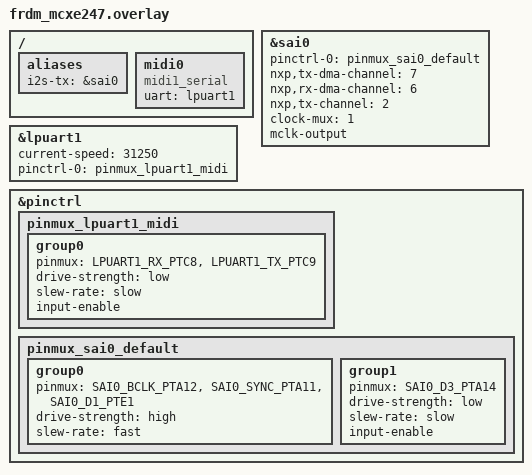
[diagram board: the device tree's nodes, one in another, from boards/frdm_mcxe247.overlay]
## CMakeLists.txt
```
# Copyright 2026 Jan-Willem Smaal <usenet@gispen.org>
# SPDX-License-Identifier: Apache-2.0

cmake_minimum_required(VERSION 3.20.0)
set(KCONFIG_ROOT ${CMAKE_CURRENT_SOURCE_DIR}/Kconfig)
find_package(Zephyr REQUIRED HINTS $ENV{ZEPHYR_BASE})
project(i2s_generator)

target_sources(app PRIVATE 
    src/main.c 
    src/generators.c
    src/shell.c
)

target_include_directories(app PRIVATE src)
```

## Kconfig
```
# Copyright 2026 Jan-Willem Smaal <usenet@gispen.org>
# SPDX-License-Identifier: Apache-2.0

menu "I2S Signal Generator Options"

config AUDIO_SAMPLE_RATE
	int "Sample Rate (Hz)"
	default 192000
	help
	  The sample rate of the generated I2S stream.

config AUDIO_BIT_WIDTH
	int "Sample Bit Width"
	default 16
	range 16 32
	help
	  The bit width of each audio sample (16 or 32).

endmenu

source "Kconfig.zephyr"
```

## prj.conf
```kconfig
CONFIG_GPIO=y
CONFIG_I2S=y
CONFIG_CMSIS_DSP=y
CONFIG_CMSIS_DSP_FASTMATH=y
CONFIG_CMSIS_DSP_BASICMATH=y
CONFIG_CMSIS_DSP_FILTERING=y
CONFIG_I2S_TX_BLOCK_COUNT=8
CONFIG_LOG=y
CONFIG_SHELL=y
CONFIG_SHELL_PROMPT_UART="I2S-Gen:~$ "
CONFIG_SHELL_VT100_COLORS=y
CONFIG_SHELL_HISTORY=y
CONFIG_SHELL_METAKEYS=y
CONFIG_SHELL_HELP=y

# Restore shell infrastructure for backspace, completion, and history
CONFIG_SHELL_VT100_COLORS=y
CONFIG_SHELL_CMDS=y
CONFIG_SHELL_HISTORY=y
CONFIG_SHELL_METAKEYS=y
CONFIG_SHELL_TAB_AUTOCOMPLETION=y
CONFIG_SHELL_HELP=y

# Keep non-shell system commands disabled for a cleaner interface
CONFIG_KERNEL_SHELL=n
CONFIG_DEVICE_SHELL=n
CONFIG_DEVMEM_SHELL=n
CONFIG_LOG_CMDS=n
CONFIG_STATS_SHELL=n
CONFIG_DATE_SHELL=n

CONFIG_CBPRINTF_FP_SUPPORT=y
CONFIG_TEST_RANDOM_GENERATOR=y

# High precision heap/stack for DSP
CONFIG_MAIN_STACK_SIZE=4096
CONFIG_SYSTEM_WORKQUEUE_STACK_SIZE=4096
```

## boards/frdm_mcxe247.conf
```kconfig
# Copyright 2026 Jan-Willem Smaal <usenet@gispen.org>
# SPDX-License-Identifier: Apache-2.0
CONFIG_I2S_HAS_PLL_SETTING=n

# Fix for a bug with the watchdog in v4.4.0 
# we need to enable the watchdog in the Kconfig
# but disable it right away at boot.
CONFIG_WATCHDOG=y
CONFIG_WDT_DISABLE_AT_BOOT=y
```

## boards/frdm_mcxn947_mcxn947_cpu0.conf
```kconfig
# MCX N-series does not use the i.MX RT style Audio PLL configuration in the SAI driver.
# Disabling this prevents a compilation error in i2s_mcux_sai.c.
CONFIG_I2S_HAS_PLL_SETTING=n
```

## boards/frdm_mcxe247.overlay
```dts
/*
 * Copyright 2026 Jan-Willem Smaal <usenet@gispen.org>
 * SPDX-License-Identifier: Apache-2.0
 */

#include <nxp/mcx/MCXE247VLQ-pinctrl.h>

/ {
	aliases {
		i2s-tx = &sai0;
	};

	midi0: midi0 {
		status = "okay";
		compatible = "midi1_serial";
		uart = <&lpuart1>;
	};
};

&sai0 {
	status = "okay";
	pinctrl-0 = <&pinmux_sai0_default>;
	pinctrl-names = "default";
	
	/* REQUIRED properties from binding documentation */
	nxp,tx-dma-channel = <7>;
	nxp,rx-dma-channel = <6>;
	
	/* User Truth: J1 Pin 5 is PTE1 which is SAI0_D1 (Channel 1) */
	nxp,tx-channel = <2>; 
	
	/* Select standard functional clock for SAI root */
	clock-mux = <1>; 
	
	mclk-output;
};

/* MIDI/Console on mikroBUS UART (PTC8/PTC9) */
&lpuart1 {
	status = "okay";
	current-speed = <31250>;
	pinctrl-0 = <&pinmux_lpuart1_midi>;
	pinctrl-names = "default";
};

&pinctrl {
	/* Standard pins with input-enable for RX */
	pinmux_lpuart1_midi: pinmux_lpuart1_midi {
		group0 {
			pinmux = <LPUART1_RX_PTC8>,
				 <LPUART1_TX_PTC9>;
			drive-strength = "low";
			slew-rate = "slow";
			input-enable;
		};
	};

	/* SAI0 (Verified User Truth Mapping) */
	pinmux_sai0_default: pinmux_sai0_default {
		group0 {
			pinmux = <SAI0_BCLK_PTA12>,   /* J1 Pin 9  - Bit Clock */
				 <SAI0_SYNC_PTA11>,   /* J1 Pin 7  - Frame Sync (LRCK) */
				 <SAI0_D1_PTE1>;      /* J1 Pin 5  - Data Out (TX_DAT) */
			drive-strength = "high";
			slew-rate = "fast";
		};
		group1 {
			pinmux = <SAI0_D3_PTA14>;     /* J1 Pin 15 - Data In (RX_DAT) */
			drive-strength = "low";
			slew-rate = "slow";
			input-enable;
		};
	};
};
```

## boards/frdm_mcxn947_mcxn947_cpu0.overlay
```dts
/*
 * Copyright 2026 Jan-Willem Smaal <usenet@gispen.org>
 * SPDX-License-Identifier: Apache-2.0
 * 
 * Proven configuration for PCM5102A on FRDM-MCXN947
 */

&sai1 {
	status = "okay";
	pinctrl-0 = <&pinmux_sai1_custom>;
	pinctrl-names = "default";
	nxp,tx-channel = <1>; /* Bitmask: 1 = Channel 0 (TXD0) */
	mclk-output;          /* MANDATORY for MCXN947 to enable internal clock generator */
};

&sai0 {
	status = "disabled";
};

&flexcomm6 {
	status = "disabled";
};

&pinctrl {
	pinmux_sai1_custom: pinmux_sai1_custom {
		group0 {
			pinmux = <SAI1_TX_BCLK_PIO3_16>,   /* J1 Pin 1  - Bit Clock */
				 <SAI1_TX_FS_PIO3_17>,     /* J1 Pin 11 - Frame Sync (LRCK) */
				 <SAI1_TXD0_PIO3_20>,      /* J1 Pin 5  - Data Out */
				 <SAI1_RX_BCLK_PIO3_18>;   /* J1 Pin 9  - Bit Clock (Swapped) */
			drive-strength = "high";
			slew-rate = "fast";
			input-enable;
		};
	};
};
```

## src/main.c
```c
/*
 * Copyright 2026 Jan-Willem Smaal <usenet@gispen.org>
 * SPDX-License-Identifier: Apache-2.0
 */

/**
 * @file main.c
 * @brief I2S Signal Generator Main Loop and Driver Integration
 * @author Jan-Willem Smaal <usenet@gispen.org>
 * @date 2026-05-27
 */

#include <zephyr/kernel.h>
#include <zephyr/drivers/i2s.h>
#include <zephyr/logging/log.h>
#include "generators.h"

LOG_MODULE_REGISTER(i2s_gen, LOG_LEVEL_INF);

#define SAMPLE_RATE CONFIG_AUDIO_SAMPLE_RATE
#define SAMPLE_BIT_WIDTH CONFIG_AUDIO_BIT_WIDTH
#define CHANNELS 2
#define SAMPLES_PER_FRAME 256
#define FRAME_SIZE (SAMPLES_PER_FRAME * CHANNELS * (SAMPLE_BIT_WIDTH / 8))
#define TX_BLOCK_COUNT 12
#define RX_BLOCK_COUNT 8

K_MEM_SLAB_DEFINE_STATIC(tx_slab, FRAME_SIZE, TX_BLOCK_COUNT, 4);
K_MEM_SLAB_DEFINE_STATIC(rx_slab, FRAME_SIZE, RX_BLOCK_COUNT, 4);

//static const struct device *const i2s_dev = DEVICE_DT_GET(DT_NODELABEL(sai1));
static const struct device *const i2s_dev = DEVICE_DT_GET(DT_ALIAS(i2s_tx));

static struct gen_state g_state;
static K_SEM_DEFINE(stream_start_sem, 0, 1);
static K_SEM_DEFINE(rx_ready_sem, 0, 1);
static bool stream_running = false;

struct gen_state *get_gen_state(void)
{
	return &g_state;
}

void audio_stream_start(void)
{
	if (!stream_running) {
		stream_running = true;
		k_sem_give(&stream_start_sem);
	}
}

void audio_stream_stop(void)
{
	if (stream_running) {
		stream_running = false;
		/* Use DROP to completely flush the TX queue and reset state */
		i2s_trigger(i2s_dev, I2S_DIR_TX, I2S_TRIGGER_DROP);
	}
}

static void audio_thread(void *p1, void *p2, void *p3)
{
	int ret;
	void *tx_buffer;

	while (1) {
		k_sem_take(&stream_start_sem, K_FOREVER);
		
		LOG_INF("Stream started");

		/* 
		 * Prime the DMA pump: On NXP MCUX SAI drivers, we MUST queue exactly 
		 * one audio block BEFORE issuing the START command.
		 */
		ret = k_mem_slab_alloc(&tx_slab, &tx_buffer, K_NO_WAIT);
		if (ret == 0) {
			gen_fill_buffer(&g_state, (int16_t *)tx_buffer, SAMPLES_PER_FRAME * CHANNELS);
			
			/* Use a block-friendly timeout to prevent EAGAIN (-35) on fast CPUs */
			ret = i2s_write(i2s_dev, tx_buffer, FRAME_SIZE);
			if (ret < 0 && ret != -EAGAIN) {
				LOG_ERR("I2S priming write failed: %d", ret);
				k_mem_slab_free(&tx_slab, tx_buffer);
				stream_running = false;
				continue;
			}
			/* If EAGAIN, we just proceed to start, the buffer wasn't queued but we'll catch up */
		}

		/* Start the hardware now that the queue has data */
		ret = i2s_trigger(i2s_dev, I2S_DIR_TX, I2S_TRIGGER_START);
		if (ret < 0) {
			LOG_ERR("I2S TX trigger start failed: %d", ret);
			stream_running = false;
			continue;
		}

		/* Main hot loop */
		while (stream_running) {
			ret = k_mem_slab_alloc(&tx_slab, &tx_buffer, K_NO_WAIT);
			if (ret < 0) {
				k_sleep(K_MSEC(1));
				continue;
			}

			gen_fill_buffer(&g_state, (int16_t *)tx_buffer, SAMPLES_PER_FRAME * CHANNELS);

			/* 
			 * Real-time audio: If the queue is full (-EAGAIN), do not block or retry.
			 * The time window has passed, so we simply drop this block and move on.
			 */
			ret = i2s_write(i2s_dev, tx_buffer, FRAME_SIZE);
			if (ret < 0) {
				k_mem_slab_free(&tx_slab, tx_buffer);
				if (ret != -EAGAIN) {
					LOG_ERR("I2S write failed: %d", ret);
					break;
				}
			}
		}
		
		LOG_INF("Stream stopped");
		stream_running = false;
	}
}

static void rx_sink_thread(void *p1, void *p2, void *p3)
{
	void *rx_buffer;
	size_t size;
	int ret;

	/* Wait for RX to be triggered in main */
	k_sem_take(&rx_ready_sem, K_FOREVER);

	while (1) {
		ret = i2s_read(i2s_dev, &rx_buffer, &size);
		if (ret == 0) {
			k_mem_slab_free(&rx_slab, rx_buffer);
		} else {
			k_sleep(K_MSEC(1));
		}
	}
}

K_THREAD_DEFINE(audio_tid, 2048, audio_thread, NULL, NULL, NULL, -2, 0, 0);
K_THREAD_DEFINE(rx_sink_tid, 1024, rx_sink_thread, NULL, NULL, NULL, -1, 0, 0);

int main(void)
{
	struct i2s_config conf;
	int ret;

	LOG_INF("I2S Signal Generator Ready.");

	if (!device_is_ready(i2s_dev)) {
		LOG_ERR("I2S device not ready");
		return -ENODEV;
	}

	conf.word_size = SAMPLE_BIT_WIDTH;
	conf.channels = CHANNELS;
	conf.format = I2S_FMT_DATA_FORMAT_I2S;
	conf.options = I2S_OPT_BIT_CLK_CONTROLLER | I2S_OPT_FRAME_CLK_CONTROLLER;
	conf.frame_clk_freq = SAMPLE_RATE;
	conf.block_size = FRAME_SIZE;
	conf.timeout = 2000;

	/* Configure TX */
	conf.mem_slab = &tx_slab;
	ret = i2s_configure(i2s_dev, I2S_DIR_TX, &conf);
	if (ret < 0) {
		LOG_ERR("I2S TX configure failed: %d", ret);
		return ret;
	}

	/* Configure RX for Clocks (Dummy Slab) */
	conf.mem_slab = &rx_slab;
	ret = i2s_configure(i2s_dev, I2S_DIR_RX, &conf);
	if (ret < 0) {
		LOG_ERR("I2S RX configure failed: %d", ret);
		return ret;
	}

	gen_init(&g_state, SAMPLE_RATE);

	/* Start Clocks (via RX). */
	ret = i2s_trigger(i2s_dev, I2S_DIR_RX, I2S_TRIGGER_START);
	if (ret < 0) {
		LOG_WRN("I2S RX (Clocks) start failed: %d", ret);
	} else {
		k_sem_give(&rx_ready_sem);
	}

	LOG_INF("Use 'gen' commands in shell to control.");

	return 0;
}
```

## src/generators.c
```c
/*
 * Copyright 2026 Jan-Willem Smaal <usenet@gispen.org>
 * SPDX-License-Identifier: Apache-2.0
 */

/**
 * @file generators.c
 * @brief CMSIS-DSP Waveform Generators Implementation (Encapsulated)
 * @author Jan-Willem Smaal <usenet@gispen.org>
 * @date 2026-05-27
 */

#include "generators.h"
#include <zephyr/random/random.h>
#include <math.h>
#include <string.h>

int gen_init(struct gen_state *state, uint32_t sample_rate)
{
	if (sample_rate == 0) {
		return -EINVAL;
	}

	memset(state, 0, sizeof(struct gen_state));
	state->type = WAVE_SINE;
	state->level = LEVEL_MAX;
	state->freq = 1000.0f;
	state->sample_rate = (float32_t)sample_rate;
	state->inv_sample_rate = 1.0f / state->sample_rate;
	state->scale = SCALE_MAX;
	
	/* Initialize safe defaults for statics */
	state->pink_indices = 1;
	state->lr_swap_left_active = true;

	return gen_set_frequency(state, state->freq);
}

void gen_set_type(struct gen_state *state, gen_type_t type)
{
	state->type = type;
	if (type == WAVE_DIRAC) {
		state->phase_acc = 0;
	}
}

int gen_set_frequency(struct gen_state *state, float freq_hz)
{
	if (freq_hz <= 0.0f || freq_hz > (state->sample_rate / 2.0f)) {
		return -EINVAL;
	}

	state->freq = freq_hz;
	/* Calculate phase increment in Q31 */
	state->phase_inc = (q31_t)((state->freq * state->inv_sample_rate) * NCO_RANGE);

	if (state->burst_active) {
		float32_t samples_per_cycle = state->sample_rate / state->freq;
		state->burst_on_samples = (uint32_t)(state->burst_on_cycles * samples_per_cycle);
		state->burst_off_samples = (uint32_t)(state->burst_off_cycles * samples_per_cycle);
	}
	
	return 0;
}

void gen_set_level(struct gen_state *state, gen_level_t level)
{
	state->level = level;
	switch (level) {
	case LEVEL_PRO:
		state->scale = SCALE_PRO;
		break;
	case LEVEL_CONSUMER:
		state->scale = SCALE_CONSUMER;
		break;
	case LEVEL_MAX:
	default:
		state->scale = SCALE_MAX;
		break;
	}
}

void gen_set_phase_offset(struct gen_state *state, float phase_deg)
{
	state->phase_offset = (q31_t)((phase_deg / DEGREES_PER_REV) * NCO_RANGE);
}

int gen_set_burst(struct gen_state *state, uint32_t on_cycles, uint32_t off_cycles)
{
	if (state->freq <= 0.0f) {
		return -EINVAL;
	}
	state->burst_on_cycles = on_cycles;
	state->burst_off_cycles = off_cycles;
	state->burst_active = true;
	state->burst_counter = 0;
	return gen_set_frequency(state, state->freq);
}

void gen_stop_burst(struct gen_state *state)
{
	state->burst_active = false;
}

int gen_set_sweep(struct gen_state *state, float start_hz, float end_hz, uint32_t duration_ms)
{
	float32_t nyquist = state->sample_rate / 2.0f;
	
	if (start_hz <= 0.0f || end_hz <= 0.0f || duration_ms == 0 ||
	    start_hz > nyquist || end_hz > nyquist) {
		return -EINVAL;
	}

	state->sweep_start_freq = start_hz;
	state->sweep_end_freq = end_hz;
	state->sweep_current_freq = start_hz;
	state->sweep_samples_current = 0;
	state->sweep_samples_total = (uint32_t)(duration_ms * (state->sample_rate / MS_PER_SEC));
	
	if (state->sweep_samples_total > 0) {
		state->sweep_multiplier = powf(end_hz / start_hz, 1.0f / (float32_t)state->sweep_samples_total);
		state->sweep_active = true;
	}
	
	return 0;
}

void gen_stop_sweep(struct gen_state *state)
{
	state->sweep_active = false;
	gen_set_frequency(state, state->freq);
}

static inline void update_sweep_phase(struct gen_state *state)
{
	if (state->sweep_active) {
		state->sweep_current_freq *= state->sweep_multiplier;
		state->sweep_samples_current++;
		
		if (state->sweep_samples_current >= state->sweep_samples_total) {
			state->sweep_current_freq = state->sweep_start_freq;
			state->sweep_samples_current = 0;
		}
		
		state->phase_inc = (q31_t)((state->sweep_current_freq * state->inv_sample_rate) * NCO_RANGE);
	}
}

static void fill_sine(struct gen_state *state, int16_t *buffer, uint32_t num_samples)
{
	for (uint32_t i = 0; i < num_samples; i += 2) {
		update_sweep_phase(state);

		q15_t angle_l = (q15_t)(state->phase_acc >> PHASE_TO_SINE_SHIFT);
		q15_t q_val_l = arm_sin_q15(angle_l);
		
		q15_t angle_r = (q15_t)((state->phase_acc + state->phase_offset) >> PHASE_TO_SINE_SHIFT);
		q15_t q_val_r = arm_sin_q15(angle_r);
		
		if (state->burst_active) {
			uint32_t period = state->burst_on_samples + state->burst_off_samples;
			if (state->burst_counter >= state->burst_on_samples) {
				q_val_l = 0;
				q_val_r = 0;
			}
			state->burst_counter++;
			if (state->burst_counter >= period) {
				state->burst_counter = 0;
			}
		}

		buffer[i] = q_val_l;
		buffer[i + 1] = q_val_r;
		
		state->phase_acc += state->phase_inc;
	}
}

static void fill_white_noise(struct gen_state *state, int16_t *buffer, uint32_t num_samples)
{
	for (uint32_t i = 0; i < num_samples; i += 2) {
		uint32_t r = sys_rand32_get();
		q15_t q_val = (q15_t)((r & UINT16_MAX) - Q15_MID_OFFSET);
		buffer[i] = q_val;
		buffer[i + 1] = q_val;
	}
}

static void fill_pink_noise(struct gen_state *state, int16_t *buffer, uint32_t num_samples)
{
	/* Pre-compute Q15 scaling factor: (1.0 / PINK_ROWS) * 32768 */
	const q15_t pink_scale_q15 = (q15_t)(32768.0f / (float32_t)PINK_ROWS);

	for (uint32_t i = 0; i < num_samples; i += 2) {
		state->pink_indices++;
		if (state->pink_indices == 0) {
			state->pink_indices = 1; /* Prevent infinite loop logic failure */
		}
		
		uint32_t tz = 0;
		uint32_t val = state->pink_indices;
		while ((val & 1) == 0) {
			tz++;
			val >>= 1;
		}

		if (tz < PINK_ROWS) {
			state->pink_running_sum -= state->pink_rows[tz];
			uint32_t r = sys_rand32_get();
			
			/* Convert random to signed Q15, then scale using 32-bit intermediate */
			q15_t raw_noise = (q15_t)((r & UINT16_MAX) - Q15_MID_OFFSET);
			state->pink_rows[tz] = (q15_t)(((int32_t)raw_noise * pink_scale_q15) >> 15);
			
			state->pink_running_sum += state->pink_rows[tz];
		}
		
		buffer[i] = state->pink_running_sum;
		buffer[i + 1] = state->pink_running_sum;
	}
}

static void fill_geometric(struct gen_state *state, int16_t *buffer, uint32_t num_samples, gen_type_t type)
{
	for (uint32_t i = 0; i < num_samples; i += 2) {
		update_sweep_phase(state);
		q15_t q_val = 0;
		if (type == WAVE_SQUARE) {
			if (state->phase_acc >= 0) {
				q_val = Q15_MAX;
			} else {
				q_val = Q15_MIN;
			}
		} else if (type == WAVE_SAWTOOTH) {
			q_val = (q15_t)(state->phase_acc >> PHASE_TO_Q15_SHIFT);
		} else if (type == WAVE_TRIANGLE) {
			q31_t temp;
			if (state->phase_acc < 0) {
				temp = ~state->phase_acc;
			} else {
				temp = state->phase_acc;
			}
			q_val = (q15_t)((temp >> TRIANGLE_Q31_SHIFT) - Q15_MID_OFFSET);
		}
		buffer[i] = q_val;
		buffer[i + 1] = q_val;
		state->phase_acc += state->phase_inc;
	}
}

static void fill_dirac(struct gen_state *state, int16_t *buffer, uint32_t num_samples)
{
	for (uint32_t i = 0; i < num_samples; i += 2) {
		q15_t q_val = 0;
		uint32_t prev_phase = (uint32_t)state->phase_acc;
		state->phase_acc += state->phase_inc;
		uint32_t curr_phase = (uint32_t)state->phase_acc;
		if (curr_phase < prev_phase) {
			q_val = Q15_MAX;
		}
		buffer[i] = q_val;
		buffer[i + 1] = q_val;
	}
}

static void fill_silence(int16_t *buffer, uint32_t num_samples)
{
	memset(buffer, 0, num_samples * sizeof(int16_t));
}

static void fill_lr_swap(struct gen_state *state, int16_t *buffer, uint32_t num_samples)
{
	for (uint32_t i = 0; i < num_samples; i += 2) {
		update_sweep_phase(state);
		q15_t angle = (q15_t)(state->phase_acc >> PHASE_TO_SINE_SHIFT);
		q15_t q_val = arm_sin_q15(angle);
		if (state->lr_swap_left_active) {
			buffer[i] = q_val;
			buffer[i + 1] = 0;
		} else {
			buffer[i] = 0;
			buffer[i + 1] = q_val;
		}
		state->phase_acc += state->phase_inc;
		state->lr_swap_timer++;
		if (state->lr_swap_timer >= (uint32_t)state->sample_rate) {
			state->lr_swap_timer = 0;
			state->lr_swap_left_active = !state->lr_swap_left_active;
		}
	}
}

static void fill_imd(struct gen_state *state, int16_t *buffer, uint32_t num_samples)
{
	const q31_t inc_low = (q31_t)((IMD_LOW_FREQ_HZ * state->inv_sample_rate) * NCO_RANGE);
	const q31_t inc_high = (q31_t)((IMD_HIGH_FREQ_HZ * state->inv_sample_rate) * NCO_RANGE);

	for (uint32_t i = 0; i < num_samples; i += 2) {
		q15_t s_low = arm_sin_q15((q15_t)(state->imd_ph_low >> PHASE_TO_SINE_SHIFT));
		q15_t s_high = arm_sin_q15((q15_t)(state->imd_ph_high >> PHASE_TO_SINE_SHIFT));
		q31_t mixed = ((q31_t)s_low * IMD_LOW_RATIO_Q15) + ((q31_t)s_high * IMD_HIGH_RATIO_Q15);
		q15_t q_val = (q15_t)(mixed >> IMD_MIX_Q31_SHIFT);
		buffer[i] = q_val;
		buffer[i + 1] = q_val;
		state->imd_ph_low += inc_low;
		state->imd_ph_high += inc_high;
	}
}

static void fill_jtest(struct gen_state *state, int16_t *buffer, uint32_t num_samples)
{
	for (uint32_t i = 0; i < num_samples; i += 2) {
		q15_t q_val;
		if ((state->jtest_sample_count / JTEST_CARRIER_DIV) % 2 == 0) {
			q_val = Q15_HALF_VAL;
		} else {
			q_val = (q15_t)-Q15_HALF_VAL;
		}
		
		if ((state->jtest_sample_count / JTEST_MOD_DIV) % 2 == 0) {
			q_val |= Q15_LSB_BIT;
		} else {
			q_val &= ~Q15_LSB_BIT;
		}
		buffer[i] = q_val;
		buffer[i + 1] = q_val;
		state->jtest_sample_count++;
	}
}

void gen_fill_buffer(struct gen_state *state, int16_t *buffer, uint32_t num_samples)
{
	switch (state->type) {
	case WAVE_SINE:
		fill_sine(state, buffer, num_samples);
		break;
	case WAVE_WHITE_NOISE:
		fill_white_noise(state, buffer, num_samples);
		break;
	case WAVE_PINK_NOISE:
		fill_pink_noise(state, buffer, num_samples);
		break;
	case WAVE_SQUARE:
	case WAVE_TRIANGLE:
	case WAVE_SAWTOOTH:
		fill_geometric(state, buffer, num_samples, state->type);
		break;
	case WAVE_DIRAC:
		fill_dirac(state, buffer, num_samples);
		break;
	case WAVE_SILENCE:
		fill_silence(buffer, num_samples);
		break;
	case WAVE_LR_SWAP:
		fill_lr_swap(state, buffer, num_samples);
		break;
	case WAVE_IMD:
		fill_imd(state, buffer, num_samples);
		break;
	case WAVE_JTEST:
		fill_jtest(state, buffer, num_samples);
		break;
	}
	
	/* Apply bulk scaling if not at full scale, except for bit-perfect J-Test */
	if (state->scale != SCALE_MAX && state->type != WAVE_JTEST && state->type != WAVE_SILENCE) {
		arm_scale_q15(buffer, state->scale, 0, buffer, num_samples);
	}
}
```

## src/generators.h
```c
/*
 * Copyright 2026 Jan-Willem Smaal <usenet@gispen.org>
 * SPDX-License-Identifier: Apache-2.0
 */

/**
 * @file generators.h
 * @brief CMSIS-DSP Waveform Generators
 * @author Jan-Willem Smaal <usenet@gispen.org>
 * @date 2026-05-27
 */

#ifndef GENERATORS_H
#define GENERATORS_H

#include <stdint.h>
#include <arm_math.h>
#include <stdbool.h>

/**
 * @brief Available waveform types for the generator.
 */
typedef enum {
	WAVE_SINE,          /**< Pure sine wave (CMSIS-DSP FastMath) */
	WAVE_SQUARE,        /**< Square wave (Fs/2 alias rich) */
	WAVE_TRIANGLE,      /**< Triangle wave */
	WAVE_SAWTOOTH,      /**< Sawtooth wave */
	WAVE_WHITE_NOISE,   /**< Flat spectrum white noise */
	WAVE_PINK_NOISE,    /**< -3dB/Octave pink noise (Voss-McCartney) */
	WAVE_DIRAC,         /**< Periodic Dirac impulse (comb) */
	WAVE_SILENCE,       /**< Digital silence (all zeros) */
	WAVE_LR_SWAP,       /**< Alternating L/R channel ID (1Hz toggle) */
	WAVE_IMD,           /**< SMPTE Intermodulation Distortion test (60Hz + 7kHz) */
	WAVE_JTEST          /**< Julian Dunn J-Test for jitter diagnostics */
} gen_type_t;

/**
 * @brief Standardized calibrated output levels.
 */
typedef enum {
	LEVEL_MAX,      /**< 0 dBFS (Maximum digital output) */
	LEVEL_PRO,      /**< +4 dBu (SMPTE/AES standard, ~ -16 dBFS) */
	LEVEL_CONSUMER  /**< -10 dBV (IEC consumer standard, ~ -28 dBFS) */
} gen_level_t;

/* Level scaling factors (Q15) 
 * Calibrated for 2.165 Vrms Full-Scale Output
 */
#define SCALE_MAX      Q15_MAX
#define SCALE_PRO      0x4899  /* 0.567 (+4 dBu) */
#define SCALE_CONSUMER 0x12AD  /* 0.146 (-10 dBV) */

/* Fixed-point and NCO constants */
#define NCO_RANGE           4294967296.0f /* 2^32 (Range of 32-bit accumulator) */
#define DEGREES_PER_REV     360.0f
#define Q15_HALF_VAL        0x4000
#define Q15_MID_OFFSET      32768         /* Offset to center unsigned noise */
#define Q15_LSB_BIT         0x0001

/* Shift constants for NCO to Q15 conversion */
#define PHASE_TO_SINE_SHIFT 17            /**< arm_sin_q15 expects 0x8000 to be 2*PI (a full cycle) */
#define PHASE_TO_Q15_SHIFT  16            /**< Shift 32-bit phase to full 16-bit amplitude */
#define TRIANGLE_Q31_SHIFT  15
#define IMD_MIX_Q31_SHIFT   15

/* Conversion constants */
#define MS_PER_SEC          1000.0f

/* Diagnostic Waveform Constants */
#define IMD_LOW_FREQ_HZ     60.0f
#define IMD_HIGH_FREQ_HZ    7000.0f
#define IMD_LOW_RATIO_Q15   26214         /* 0.8 in Q15 */
#define IMD_HIGH_RATIO_Q15  6554          /* 0.2 in Q15 */

#define JTEST_CARRIER_DIV   2             /* Fs/4 (toggles every 2 samples) */
#define JTEST_MOD_DIV       96            /* Fs/192 (toggles every 96 samples) */

#define PINK_ROWS 12

/**
 * @brief Encapsulated state context for the signal generator.
 * 
 * This structure holds all the configuration, phase accumulators, and history
 * required to generate the audio streams without relying on global variables.
 */
struct gen_state {
	gen_type_t type;            /**< Current waveform type */
	gen_level_t level;          /**< Current calibrated output level */
	float32_t freq;             /**< Base frequency in Hz */
	float32_t sample_rate;      /**< System sample rate in Hz */
	float32_t inv_sample_rate;  /**< Pre-calculated 1/Fs for performance */
	q15_t scale;                /**< Current Q15 scaling factor */

	/* Phase accumulator */
	q31_t phase_acc;            /**< 32-bit Numerically Controlled Oscillator phase */
	q31_t phase_inc;            /**< Phase step per sample */
	q31_t phase_offset;         /**< Phase offset applied to the Right channel */

	/* Burst state */
	bool burst_active;          /**< True if tone burst mode is enabled */
	uint32_t burst_on_cycles;   /**< Number of full cycles the tone is ON */
	uint32_t burst_off_cycles;  /**< Number of full cycles the tone is OFF */
	uint32_t burst_on_samples;  /**< Calculated number of ON samples */
	uint32_t burst_off_samples; /**< Calculated number of OFF samples */
	uint32_t burst_counter;     /**< Running counter for burst state machine */

	/* Sweep state */
	bool sweep_active;          /**< True if logarithmic sweep is running */
	float32_t sweep_start_freq; /**< Sweep start frequency (Hz) */
	float32_t sweep_end_freq;   /**< Sweep end frequency (Hz) */
	float32_t sweep_current_freq;/**< Current instantaneous frequency of the sweep */
	float32_t sweep_multiplier; /**< Per-sample frequency multiplier for log sweep */
	uint32_t sweep_samples_total;/**< Total number of samples in the sweep duration */
	uint32_t sweep_samples_current;/**< Current sample index in the sweep */

	/* Pink noise state */
	uint32_t pink_indices;      /**< Running index for Voss-McCartney algorithm */
	q15_t pink_rows[PINK_ROWS]; /**< State array for noise generators */
	q15_t pink_running_sum;     /**< Running sum of the noise generators */

	/* Diagnostic specific state */
	uint32_t lr_swap_timer;     /**< Timer for L/R channel swap toggle */
	bool lr_swap_left_active;   /**< State flag for L/R channel swap */
	q31_t imd_ph_low;           /**< Phase accumulator for IMD 60Hz carrier */
	q31_t imd_ph_high;          /**< Phase accumulator for IMD 7kHz modulation */
	uint32_t jtest_sample_count;/**< Running sample counter for J-Test toggling */
};

/**
 * @brief Initialize the generator state.
 * @param state Pointer to the generator state structure.
 * @param sample_rate The system sample rate in Hz (e.g., 48000, 192000).
 * @return 0 on success, or negative error code.
 */
int gen_init(struct gen_state *state, uint32_t sample_rate);

/**
 * @brief Set the active waveform type.
 * @param state Pointer to the generator state structure.
 * @param type The desired waveform type.
 */
void gen_set_type(struct gen_state *state, gen_type_t type);

/**
 * @brief Set the fundamental frequency.
 * @param state Pointer to the generator state structure.
 * @param freq_hz Frequency in Hertz.
 * @return 0 on success, or negative error code if invalid bounds.
 */
int gen_set_frequency(struct gen_state *state, float freq_hz);

/**
 * @brief Set the calibrated output level.
 * @param state Pointer to the generator state structure.
 * @param level The desired output level (MAX, PRO, CONSUMER).
 */
void gen_set_level(struct gen_state *state, gen_level_t level);

/**
 * @brief Set the phase offset for the Right channel.
 * @param state Pointer to the generator state structure.
 * @param phase_deg Phase shift in degrees (0.0 to 360.0).
 */
void gen_set_phase_offset(struct gen_state *state, float phase_deg);

/**
 * @brief Enable Tone Burst mode (typically for Sine waves).
 * @param state Pointer to the generator state structure.
 * @param on_cycles Number of complete wave cycles the signal is active.
 * @param off_cycles Number of complete wave cycles the signal is muted.
 * @return 0 on success, or negative error code if frequency is invalid.
 */
int gen_set_burst(struct gen_state *state, uint32_t on_cycles, uint32_t off_cycles);

/**
 * @brief Disable Tone Burst mode.
 * @param state Pointer to the generator state structure.
 */
void gen_stop_burst(struct gen_state *state);

/**
 * @brief Start a logarithmic frequency sweep.
 * @param state Pointer to the generator state structure.
 * @param start_hz Starting frequency in Hertz.
 * @param end_hz Ending frequency in Hertz.
 * @param duration_ms Total duration of the sweep in milliseconds.
 * @return 0 on success, or negative error code.
 */
int gen_set_sweep(struct gen_state *state, float start_hz, float end_hz, uint32_t duration_ms);

/**
 * @brief Stop the active frequency sweep.
 * @param state Pointer to the generator state structure.
 */
void gen_stop_sweep(struct gen_state *state);

/**
 * @brief Generate the next block of interleaved audio samples.
 * @param state Pointer to the generator state structure.
 * @param buffer Pointer to the destination buffer (must be large enough).
 * @param num_samples Total number of samples to generate (Left + Right).
 */
void gen_fill_buffer(struct gen_state *state, int16_t *buffer, uint32_t num_samples);

#endif /* GENERATORS_H */
```

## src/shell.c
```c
/*
 * Copyright 2026 Jan-Willem Smaal <usenet@gispen.org>
 * SPDX-License-Identifier: Apache-2.0
 */

/**
 * @file shell.c
 * @brief Shell Commands for I2S Signal Generator (Encapsulated)
 * @author Jan-Willem Smaal <usenet@gispen.org>
 * @date 2026-05-27
 */

#include <zephyr/shell/shell.h>
#include <stdlib.h>
#include <string.h>
#include "generators.h"

/* Forward declaration from main.c */
extern struct gen_state *get_gen_state(void);
extern void audio_stream_start(void);
extern void audio_stream_stop(void);

static int cmd_gen_start(const struct shell *sh, size_t argc, char **argv) { audio_stream_start(); return 0; }
static int cmd_gen_stop(const struct shell *sh, size_t argc, char **argv) { audio_stream_stop(); return 0; }

static int cmd_gen_wave_sine(const struct shell *sh, size_t argc, char **argv) { gen_set_type(get_gen_state(), WAVE_SINE); return 0; }
static int cmd_gen_wave_square(const struct shell *sh, size_t argc, char **argv) { gen_set_type(get_gen_state(), WAVE_SQUARE); return 0; }
static int cmd_gen_wave_triangle(const struct shell *sh, size_t argc, char **argv) { gen_set_type(get_gen_state(), WAVE_TRIANGLE); return 0; }
static int cmd_gen_wave_saw(const struct shell *sh, size_t argc, char **argv) { gen_set_type(get_gen_state(), WAVE_SAWTOOTH); return 0; }
static int cmd_gen_wave_white(const struct shell *sh, size_t argc, char **argv) { gen_set_type(get_gen_state(), WAVE_WHITE_NOISE); return 0; }
static int cmd_gen_wave_pink(const struct shell *sh, size_t argc, char **argv) { gen_set_type(get_gen_state(), WAVE_PINK_NOISE); return 0; }
static int cmd_gen_wave_dirac(const struct shell *sh, size_t argc, char **argv) { gen_set_type(get_gen_state(), WAVE_DIRAC); return 0; }
static int cmd_gen_wave_silence(const struct shell *sh, size_t argc, char **argv) { gen_set_type(get_gen_state(), WAVE_SILENCE); return 0; }
static int cmd_gen_wave_lrswap(const struct shell *sh, size_t argc, char **argv) { gen_set_type(get_gen_state(), WAVE_LR_SWAP); return 0; }
static int cmd_gen_wave_imd(const struct shell *sh, size_t argc, char **argv) { gen_set_type(get_gen_state(), WAVE_IMD); return 0; }
static int cmd_gen_wave_jtest(const struct shell *sh, size_t argc, char **argv) { gen_set_type(get_gen_state(), WAVE_JTEST); return 0; }

SHELL_STATIC_SUBCMD_SET_CREATE(sub_gen_wave,
	SHELL_CMD(sine, NULL, "Sine wave", cmd_gen_wave_sine),
	SHELL_CMD(square, NULL, "Square wave", cmd_gen_wave_square),
	SHELL_CMD(triangle, NULL, "Triangle wave", cmd_gen_wave_triangle),
	SHELL_CMD(saw, NULL, "Sawtooth wave", cmd_gen_wave_saw),
	SHELL_CMD(white, NULL, "White noise", cmd_gen_wave_white),
	SHELL_CMD(pink, NULL, "Pink noise", cmd_gen_wave_pink),
	SHELL_CMD(dirac, NULL, "Dirac comb (periodic impulse)", cmd_gen_wave_dirac),
	SHELL_CMD(silence, NULL, "Digital silence", cmd_gen_wave_silence),
	SHELL_CMD(lrswap, NULL, "L/R channel ID (alternating)", cmd_gen_wave_lrswap),
	SHELL_CMD(imd, NULL, "IMD test (SMPTE 60Hz + 7kHz)", cmd_gen_wave_imd),
	SHELL_CMD(jtest, NULL, "J-Test jitter diagnostic", cmd_gen_wave_jtest),
	SHELL_SUBCMD_SET_END
);

static int cmd_gen_freq(const struct shell *sh, size_t argc, char **argv)
{
	float freq = atof(argv[1]);
	if (freq <= 0.0f) {
		shell_error(sh, "Invalid frequency: %s", argv[1]);
		return -EINVAL;
	}
	int ret = gen_set_frequency(get_gen_state(), freq);
	if (ret < 0) {
		shell_error(sh, "Frequency out of bounds (max %.1f Hz)", (double)(get_gen_state()->sample_rate / 2.0f));
		return ret;
	}
	shell_print(sh, "Frequency set to: %.2f Hz", (double)freq);
	return 0;
}

static int cmd_gen_level(const struct shell *sh, size_t argc, char **argv)
{
	struct gen_state *state = get_gen_state();
	if (strcmp(argv[1], "pro") == 0) {
		gen_set_level(state, LEVEL_PRO);
	} else if (strcmp(argv[1], "consumer") == 0) {
		gen_set_level(state, LEVEL_CONSUMER);
	} else if (strcmp(argv[1], "max") == 0) {
		gen_set_level(state, LEVEL_MAX);
	} else {
		shell_error(sh, "Unknown level type: %s (use pro, consumer, max)", argv[1]);
		return -EINVAL;
	}
	shell_print(sh, "Output level set to: %s", argv[1]);
	return 0;
}

static int cmd_gen_phase(const struct shell *sh, size_t argc, char **argv)
{
	float phase = atof(argv[1]);
	gen_set_phase_offset(get_gen_state(), phase);
	shell_print(sh, "Right channel phase offset set to: %.2f degrees", (double)phase);
	return 0;
}

static int cmd_gen_burst_start(const struct shell *sh, size_t argc, char **argv)
{
	uint32_t on = atoi(argv[1]);
	uint32_t off = atoi(argv[2]);
	if (on == 0) {
		shell_error(sh, "On-cycles must be > 0");
		return -EINVAL;
	}
	int ret = gen_set_burst(get_gen_state(), on, off);
	if (ret < 0) {
		shell_error(sh, "Cannot start burst: invalid base frequency");
		return ret;
	}
	shell_print(sh, "Tone burst started: %u cycles on, %u cycles off", on, off);
	return 0;
}

static int cmd_gen_burst_stop(const struct shell *sh, size_t argc, char **argv)
{
	gen_stop_burst(get_gen_state());
	shell_print(sh, "Tone burst disabled.");
	return 0;
}

static int cmd_gen_sweep_start(const struct shell *sh, size_t argc, char **argv)
{
	float start_hz = atof(argv[1]);
	float end_hz = atof(argv[2]);
	uint32_t duration_ms = atoi(argv[3]);

	int ret = gen_set_sweep(get_gen_state(), start_hz, end_hz, duration_ms);
	if (ret < 0) {
		shell_error(sh, "Invalid sweep parameters or out of bounds (max %.1f Hz)", (double)(get_gen_state()->sample_rate / 2.0f));
		return ret;
	}

	shell_print(sh, "Logarithmic sweep started: %.2f Hz -> %.2f Hz over %u ms",
		    (double)start_hz, (double)end_hz, duration_ms);
	return 0;
}

static int cmd_gen_sweep_stop(const struct shell *sh, size_t argc, char **argv)
{
	gen_stop_sweep(get_gen_state());
	shell_print(sh, "Sweep stopped.");
	return 0;
}

SHELL_STATIC_SUBCMD_SET_CREATE(sub_gen_sweep,
	SHELL_CMD_ARG(start, NULL, "Start log sweep <start_hz> <end_hz> <duration_ms>", cmd_gen_sweep_start, 4, 0),
	SHELL_CMD(stop, NULL, "Stop frequency sweep", cmd_gen_sweep_stop),
	SHELL_SUBCMD_SET_END
);

SHELL_STATIC_SUBCMD_SET_CREATE(sub_gen_burst,
	SHELL_CMD_ARG(start, NULL, "Start burst <on_cycles> <off_cycles>", cmd_gen_burst_start, 3, 0),
	SHELL_CMD(stop, NULL, "Stop burst mode", cmd_gen_burst_stop),
	SHELL_SUBCMD_SET_END
);

SHELL_STATIC_SUBCMD_SET_CREATE(sub_gen,
	SHELL_CMD(start, NULL, "Start I2S stream", cmd_gen_start),
	SHELL_CMD(stop, NULL, "Stop I2S stream", cmd_gen_stop),
	SHELL_CMD(wave, &sub_gen_wave, "Select waveform type", NULL),
	SHELL_CMD_ARG(freq, NULL, "Set frequency <hz>", cmd_gen_freq, 2, 0),
	SHELL_CMD_ARG(level, NULL, "Set level <pro|consumer|max>", cmd_gen_level, 2, 0),
	SHELL_CMD_ARG(phase, NULL, "Set R-channel phase offset <degrees>", cmd_gen_phase, 2, 0),
	SHELL_CMD(burst, &sub_gen_burst, "Tone burst control", NULL),
	SHELL_CMD(sweep, &sub_gen_sweep, "Frequency sweep control", NULL),
	SHELL_SUBCMD_SET_END
);

SHELL_CMD_REGISTER(gen, &sub_gen, "I2S Generator commands", NULL);
```
